# MINI register map
Registers are access not given, no defined reset value unless marked. A register's access mark holds for its fields unless they carry their own. Offsets are from the block's base; lines under a group give offsets from that group; [hi:lo] are bit positions; {n}, {i} and the like mark numbered series; 'fields as' and 'values as' point back to an identical list; <NAME> marks a mode.

## Memory map
0x40000000 GPIO — General purpose input/output
0x40001000 GPIO1
0x40002000 DMA

## GPIO — General purpose input/output
Base 0x40000000
Same registers: GPIO1 0x40001000
0x04 OUT — Output levels
  [31:0] DATA
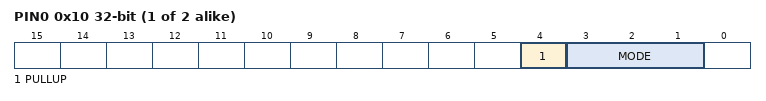
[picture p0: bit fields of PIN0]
{0x10+4i} PIN{i} (i=0..1) — Configuration of pin {i}
  [4] PULLUP
  [3:1] MODE — Mode of pin %s

## DMA
Base 0x40002000
{0x100+0x20*i} CH[{i}] (i=0..1) group
  0x08 CTRL
    [0] EN
